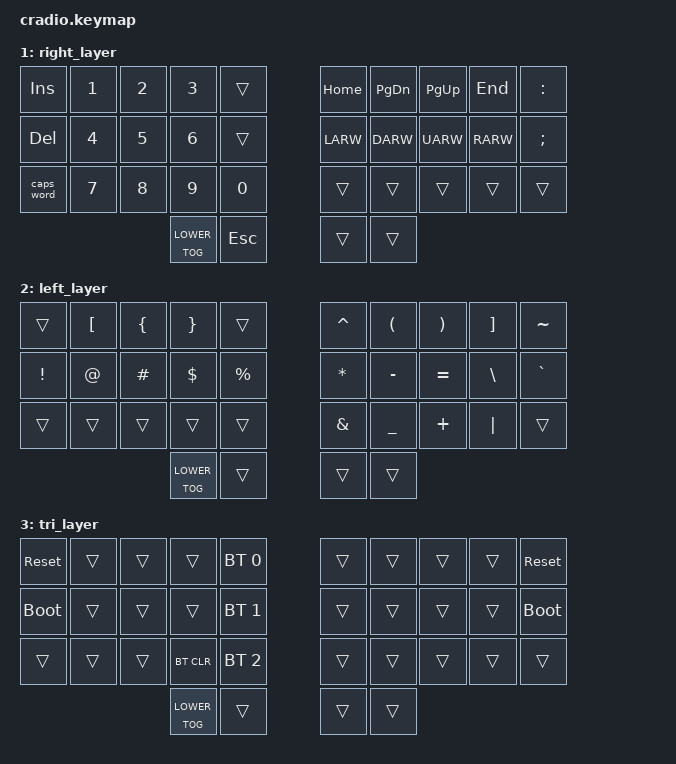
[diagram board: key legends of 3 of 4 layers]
// Copyright (c) 2022 The ZMK Contributors
// SPDX-License-Identifier: MIT

#include <behaviors.dtsi>
#include <dt-bindings/zmk/keys.h>
#include <dt-bindings/zmk/bt.h>

// Home row mods macro
#define HRML(k1,k2,k3,k4) &ht LSHFT k1  &ht LALT k2  &ht LCTRL k3  &ht LGUI k4
#define HRMR(k1,k2,k3,k4) &ht RGUI k1  &ht RCTRL k2  &ht RALT k3  &ht RSHFT k4

/ {
    behaviors {
        ht: hold_tap {
            compatible = "zmk,behavior-hold-tap";
            #binding-cells = <2>;
            flavor = "tap-preferred";
            tapping-term-ms = <220>;
            quick-tap-ms = <150>;
            require-prior-idle-ms = <100>;
            bindings = <&kp>, <&kp>;
        };
};
&mt {
    tapping-term-ms = <400>;
    };

    conditional_layers {
        compatible = "zmk,conditional-layers";
        tri_layer {
            if-layers = <1 2>;
            then-layer = <3>;
        };
    };

    keymap {
        compatible = "zmk,keymap";
        default_layer {
            bindings = <
        //╭──────────┬──────────┬──────────┬──────────┬──────────╮   ╭──────────┬──────────┬──────────┬──────────┬─────────╮
        //│  Q       │  W       │  F       │  P       │  b       │   │  j       │  l       │  u       │  y       │  ;       │
            &kp Q      &kp W      &kp F      &kp p      &kp b          &kp j     &kp l      &kp u      &kp y      &kp SEMICOLON
        //├──────────┼──────────┼──────────┼──────────┼──────────┤   ├──────────┼──────────┼──────────┼──────────┼──────────┤
        //│  A       │  S       │  r       │  t       │  g       │   │  m       │  n      │  e       │  i       │ o     │
            HRML(A,        S,         r,         t)     &kp G          &kp m      HRMR(n,       e,         i,        o)
        //├──────────┼──────────┼──────────┼──────────┼──────────┤   ├──────────┼──────────┼──────────┼──────────┼──────────┤
        //│  Z       │  X       │  C       │  d       │  v       │   │  k       │  h      │ , <      │ . >      │ / ?      │
          &mt LCTRL Z      &kp X      &kp C      &kp d     &kp v          &kp k      &kp h      &kp COMMA  &kp DOT    &kp FSLH
        //╰──────────┴──────────┴──────────┼──────────┼──────────┤   ├──────────┼──────────┼──────────┴──────────┴──────────╯
                                           &TOG LOWER  &lt 2 BSPC       &kp ENTER  &lt 1 SPACE
        //                                 ╰──────────┴──────────╯   ╰──────────┴──────────╯
            >;
        };

        right_layer {
            bindings = <
        //╭──────────┬──────────┬──────────┬──────────┬──────────╮   ╭──────────┬──────────┬──────────┬──────────┬──────────╮
        //│ INSERT   │  1       │  2       │  3       │          │   │ HOME     │ PAGE DN  │ PAGE UP  │ END      │  :       │
            &kp INS    &kp N1     &kp N2     &kp N3     &trans         &kp HOME   &kp PG_DN  &kp PG_UP  &kp END    &kp COLON
        //├──────────┼──────────┼──────────┼──────────┼──────────┤   ├──────────┼──────────┼──────────┼──────────┼──────────┤
        //│ DELETE   │  4       │  5       │  6       │          │   │ LEFT     │ DOWN     │ UP       │ RIGHT    │  ;       │
            &kp DEL    &kp N4     &kp N5     &kp N6     &trans         &kp LARW   &kp DARW   &kp UARW   &kp RARW   &kp SEMI
        //├──────────┼──────────┼──────────┼──────────┼──────────┤   ├──────────┼──────────┼──────────┼──────────┼──────────┤
        //│ CAPS     │  7       │  8       │  9       │  0       │   │          │          │          │          │          │
           &caps_word  &kp N7     &kp N8     &kp N9     &kp N0         &trans     &trans     &trans     &trans     &trans
        //╰──────────┴──────────┴──────────┼──────────┼──────────┤   ├──────────┼──────────┼──────────┴──────────┴──────────╯
                                             &TOG LOWER    &kp ESC        &trans     &trans
        //                                 ╰──────────┴──────────╯   ╰──────────┴──────────╯
            >;
        };

        left_layer {
            bindings = <
        //╭──────────┬──────────┬──────────┬──────────┬──────────╮   ╭──────────┬──────────┬──────────┬──────────┬──────────╮
        //│          │  [       │  {       │  }       │          │   │  ^       │  (       │  )       │  ]       │  ~       │
            &trans     &kp LBKT   &kp LBRC   &kp RBRC   &trans         &kp CARET  &kp LPAR   &kp RPAR   &kp RBKT   &kp TILDE
        //├──────────┼──────────┼──────────┼──────────┼──────────┤   ├──────────┼──────────┼──────────┼──────────┼──────────┤
        //│  !       │  @       │  #       │  $       │  %       │   │  *       │  -       │  =       │  \       │  `       │
            &kp EXCL   &kp AT     &kp HASH   &kp DLLR   &kp PRCNT      &kp ASTRK  &kp MINUS  &kp EQUAL  &kp BSLH   &kp GRAVE
        //├──────────┼──────────┼──────────┼──────────┼──────────┤   ├──────────┼──────────┼──────────┼──────────┼──────────┤
        //│          │          │          │          │          │   │  &       │  _       │  +       │  │       │          │
            &trans     &trans     &trans     &trans     &trans         &kp AMPS   &kp UNDER  &kp PLUS   &kp PIPE   &trans
        //╰──────────┴──────────┴──────────┼──────────┼──────────┤   ├──────────┼──────────┼──────────┴──────────┴──────────╯
                                             &TOG LOWER     &trans         &trans     &trans
        //                                 ╰──────────┴──────────╯   ╰──────────┴──────────╯
            >;
        };

        tri_layer {
            bindings = <
        //╭──────────┬──────────┬──────────┬──────────┬──────────╮   ╭──────────┬──────────┬──────────┬──────────┬──────────╮
        //│ RESET    │          │          │          │PROFILE 0 │   │          │          │          │          │  RESET   │
           &sys_reset  &trans     &trans     &trans    &bt BT_SEL 0    &trans     &trans     &trans     &trans    &sys_reset
        //├──────────┼──────────┼──────────┼──────────┼──────────┤   ├──────────┼──────────┼──────────┼──────────┼──────────┤
        //│BOOTLOADER│          │          │          │PROFILE 1 │   │          │          │          │          │BOOTLOADER│
          &bootloader  &trans     &trans     &trans    &bt BT_SEL 1    &trans     &trans     &trans     &trans    &bootloader
        //├──────────┼──────────┼──────────┼──────────┼──────────┤   ├──────────┼──────────┼──────────┼──────────┼──────────┤
        //│          │          │          │ CLEAR BT │PROFILE 2 │   │          │          │          │          │          │
            &trans     &trans     &trans    &bt BT_CLR &bt BT_SEL 2    &trans     &trans     &trans     &trans     &trans
        //╰──────────┴──────────┴──────────┼──────────┼──────────┤   ├──────────┼──────────┼──────────┴──────────┴──────────╯
                                             &TOG LOWER     &trans         &trans     &trans
        //                                 ╰──────────┴──────────╯   ╰──────────┴──────────╯
            >;
        };
    };
};
